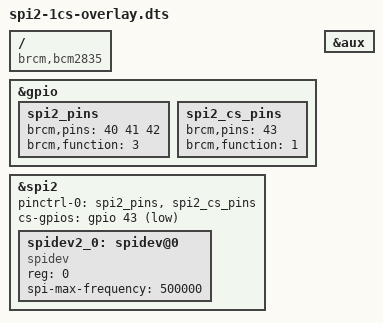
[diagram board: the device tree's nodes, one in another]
/dts-v1/;
/plugin/;


/ {
	compatible = "brcm,bcm2835", "brcm,bcm2708", "brcm,bcm2709";

	fragment@0 {
		target = <&gpio>;
		__overlay__ {
			spi2_pins: spi2_pins {
				brcm,pins = <40 41 42>;
				brcm,function = <3>; /* alt4 */
			};

			spi2_cs_pins: spi2_cs_pins {
				brcm,pins = <43>;
				brcm,function = <1>; /* output */
			};
		};
	};

	fragment@1 {
		target = <&spi2>;
		frag1: __overlay__ {
			/* needed to avoid dtc warning */
			#address-cells = <1>;
			#size-cells = <0>;
			pinctrl-names = "default";
			pinctrl-0 = <&spi2_pins &spi2_cs_pins>;
			cs-gpios = <&gpio 43 1>;
			status = "okay";

			spidev2_0: spidev@0 {
				compatible = "spidev";
				reg = <0>;      /* CE0 */
				#address-cells = <1>;
				#size-cells = <0>;
				spi-max-frequency = <500000>;
				status = "okay";
			};
		};
	};

	fragment@2 {
		target = <&aux>;
		__overlay__ {
			status = "okay";
		};
	};

	__overrides__ {
		cs0_pin  = <&spi2_cs_pins>,"brcm,pins:0",
			   <&frag1>,"cs-gpios:4";
		cs0_spidev = <&spidev2_0>,"status";
	};
};
